# MCASP1_CFG register map
Vendor: Texas Instruments
Peripheral module from a debugger description file (folder TDA2Px).
Registers are 32-bit, read-write, reset values left out (the file's numbers can be read two ways) unless marked. A register's access mark holds for its fields unless they carry their own. Offsets are as the file gives them; lines under a group give offsets from that group; [hi:lo] are bit positions; {n}, {i} and the like mark numbered series; 'fields as' and 'values as' point back to an identical list; <NAME> marks a mode.

## MCASP1_CFG (part 1 of 2)
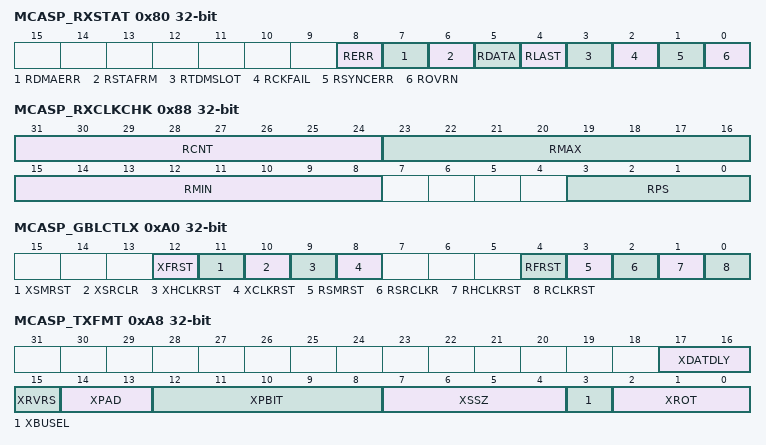
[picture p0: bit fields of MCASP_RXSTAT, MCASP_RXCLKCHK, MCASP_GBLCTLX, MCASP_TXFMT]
0x80 MCASP_RXSTAT — The receiver status register () provides the receiver status and receive TDM time slot number.
  [8] RERR — RERR bit always returns a logic-OR of: ROVRN | RSYNCERR | RCKFAIL | RDMAERR Allows a single bit to be checked to determine if a receiver error has occurred.
    0=NOERROR (No errors have occurred.); 1=ERROR (An error has occurred.)
  [7] RDMAERR — Receive DMA error flag. RDMAERR is set when the CPU or DMA reads more serializers through the DMA port in a given time slot than were programmed as receivers. This bit is cleared by writing a 1 to this bit. Writing a 0 to this bit has no effect.
    0=NOTOCCUR (Receive DMA error did not occur.); 1=OCCUR (Receive DMA error did occur.)
  [6] RSTAFRM — Receive start of frame flag. This bit is cleared by writing a 1 to this bit. Writing a 0 to this bit has no effect.
    0=NOTOCCUR (No new receive frame sync (AFSR) is detected.); 1=OCCUR (A new receive frame sync (AFSR) is detected.)
  [5] RDATA — Receive data ready flag. This bit is cleared by writing a 1 to this bit. Writing a 0 to this bit has no effect.
    0=NOTOCCUR (No new data in RBUF.); 1=OCCUR (Data is transferred from XRSR to RBUF and ready to be serviced by the CPUs or DMA.When RDATA is set, it always causes a DMA event (AREVT).)
  [4] RLAST — Receive last slot flag. RLAST is set along with RDATA, if the current slot is the last slot in a frame. This bit is cleared by writing a 1 to this bit. Writing a 0 to this bit has no effect.
    0=NOTOCCUR (Current slot is not the last slot in a frame.); 1=OCCUR (Current slot is the last slot in a frame. RDATA is also set.)
  [3] RTDMSLOT — Returns the LSB of RSLOT. Allows a single read ofMCASP_RXSTAT to determine whether the current TDM time slot is even or odd.
    0=ODDSLOT (Current TDM time slot is odd.); 1=EVENSLOT (Current TDM time slot is even.)
  [2] RCKFAIL — Receive clock failure flag. RCKFAIL is set when the receive clock failure detection circuit reports an error. This bit is cleared by writing a 1 to this bit. Writing a 0 to this bit has no effect.
    0=NOTOCCUR (Receive clock failure did not occur.); 1=OCCUR (Receive clock failure did occur.)
  [1] RSYNCERR — Unexpected receive frame sync flag. RSYNCERR is set when a new receive frame sync (AFSR) occurs before it is expected. This bit is cleared by writing a 1 to this bit. Writing a 0 to this bit has no effect.
    0=NOTOCCUR (Unexpected receive frame sync did not occur.); 1=OCCUR (Unexpected receive frame sync did occur.)
  [0] ROVRN — Receiver overrun flag. ROVRN is set when the receive serializer is instructed to transfer data from XRSR to RBUF, but the former data in RBUF has not yet been read by the CPU or DMA. This bit is cleared by writing a 1 to this bit. Writing a 0 to this bit has no effect.
    0=NOTOCCUR (Receiver overrun did not occur.); 1=OCCUR (Receiver overrun did occur.)
0x84 MCASP_RXTDMSLOT ro — The current receive TDM time slot register () indicates the current time slot for the receive data frame.
  [8:0] RSLOTCNT — 0x0 - 0x17F: Current receive time slot count. Legal values: 0 to 383 (17Fh). TDM function is not supported for &gt; 32 time slots. However, TDM time slot counter may count to 383 when used to receive a DIR block (transferred over TDM format).
0x88 MCASP_RXCLKCHK access per field — The receive clock check control register (RCLKCHK) configures the receive clock failure detection circuit.
  [31:24] RCNT ro — 0x0 - 0xFF: Receive clock count value (from previous measurement). The clock circuit continually counts the number of interface clocks for every 32 receive high-frequency master clock (AHCLKR) signals, and stores the count in RCNT until the next measurement is taken.
  [23:16] RMAX rw — 0x00-0xFF: Receive clock maximum boundary. This 8-bit unsigned value sets the maximum allowed boundary for the clock check counter after 32 receive high-frequency master clock (AHCLKR) signals have been received. If the current counter value is greater than RMAX after counting 32 AHCLKR signals, RCKFAIL inMCASP_RXSTAT is set. The comparison is performed using unsigned arithmetic.
  [15:8] RMIN rw — 0x00 - 0xFF: Receive clock minimum boundary. This 8-bit unsigned value sets the minimum allowed boundary for the clock check counter after 32 receive high-frequency master clock (AHCLKR) signals have been received. If RCNT is less than RMIN after counting 32 AHCLKR signals, RCKFAIL in RSTAT is set. The comparison is performed using unsigned arithmetic.
  [3:0] RPS rw — Receive clock check prescaler value.0x9 - 0xF: Reserved enum=DIVBY8 .
    0=DIVBY64 (MCASP interface clock divided by 1); 1=DIVBY2 (MCASP interface clock divided by 2); 2=DIVBY128 (MCASP interface clock divided by 4); 3=DIVBY1 (MCASP interface clock divided by 8); 4=DIVBY4 (MCASP interface clock divided by 16); 5=DIVBY256 (MCASP interface clock divided by 32); 6=DIVBY16 (MCASP interface clock divided by 64); 7=DIVBY32 (MCASP interface clock divided by 128); 8=DIVBY8 (MCASP interface clock divided by 256)
0x8C MCASP_REVTCTL — Receiver DMA event control register
  [0] RDATDMA — Receive data DMA request enable bit.
    0=DMA_0 (The receive data DMA request is enabled.); 1=DMA_1 (The receive data DMA request is disabled.)
0xA0 MCASP_GBLCTLX access per field — Alias of GBLCTL. When writing to this register, only the TRANSMIT bits of GBLCTL are affected (This means GBLCTL bits 8,9,10,11,12.). Reads return GBLCTL.
  [12] XFRST rw — Frame sync generator reset
    0=RESET; 1=ACTIVE
  [11] XSMRST rw — XMT state machine reset
    0=RESET; 1=ACTIVE
  [10] XSRCLR rw — XMT serializer clear
    0=CLEAR; 1=ACTIVE
  [9] XHCLKRST rw — XMT High Freq. clk Divider
    0=RESET; 1=ACTIVE
  [8] XCLKRST rw — XMT clock divder reset
    0=RESET; 1=ACTIVE
  [4] RFRST ro — Frame sync generator reset
    0=RESET; 1=ACTIVE
  [3] RSMRST ro — RCV state machine reset
    0=RESET; 1=ACTIVE
  [2] RSRCLKR ro — RCV serializer clear
    0=CLEAR; 1=ACTIVE
  [1] RHCLKRST ro — RCV High Freq. clk Divider
    0=RESET; 1=ACTIVE
  [0] RCLKRST ro — RCV clock divder reset
    0=RESET; 1=ACTIVE
0xA4 MCASP_TXMASK — Transmit format unit bit mask register - Determines which bits of the transmitted data are masked off before being shifted out the MCASP
  [31:0] XMASK_31_0 — Transmit data mask enable bit
    0=MCASP_0 (The corresponding bit of transmit data is masked out and then transmitted out the MCASP in place of the original bit.); 1=MCASP._1 (The corresponding bit of transmit data is transmitted out the MCASP.)
0xA8 MCASP_TXFMT — Transmit bitstream format register - configures the transmit data format
  [17:16] XDATDLY — Transmit sync bit delay
    0=0BIT (0 bit delay - The first transmit data bit, on the AXR[n], occurs in the same mcaspi_aclkx cycle as the transmit frame sync (mcaspi_fsx).); 1=1BIT (1-bit delay. The first transmit data bit, AXR[n], occurs one ACLKX cycle after the transmit frame sync (AFSX).); 2=2BIT (2-bit delay. The first transmit data bit, AXR[n], occurs two ACLKX cycles after the transmit frame sync (AFSX).); 3=2BIT (Reserved)
  [15] XRVRS — Transmit serial bitstream order
    0=LSB_0 (Bitstream is LSB first. No bit reversal is performed in transmit format unit.); 1=MSB_1 (Bitstream is MSB first. Bit reversal is performed in transmit format bit reverse unit.)
  [14:13] XPAD — Pad value for extra bits in slot not belonging to word defined by XMASK. This field only applies to bits when XMASK[n] = 0.
    0=Pad_extra_bits_with_0; 1=Pad_extra_bits_with_1; 2=XPBIT_2 (Pad extra bits with one of the bits from the word as specified by XPBIT bits.)
  [12:8] XPBIT — XPBIT value determines which bit (as written by the CPU or DMA to XBUF[n]) is used to pad the extra bits before shifting. This field only applies when XPAD = 0x2.
  [7:4] XSSZ — Transmit slot size0x0 - 0x2 : Reserved enum=RSV8 .
    3=RSV8 (Slot size is 8 bits); 4=RSV8 (Reserved); 5=RSV8 (Slot size is 12 bits); 6=RSV8 (Reserved); 7=RSV8 (Slot size is 16 bits); 8=RSV8 (Reserved); 9=RSV8 (Slot size is 20 bits); 10=RSV8 (Reserved); 11=RSV8 (Slot size is 24 bits); 12=RSV8 (Reserved); 13=RSV8 (Slot size is 28 bits); 14=RSV8 (Reserved); 15=Slot_size_is_32_bits
  [3] XBUSEL — Selects whether writes to the serializer buffer XBUF[n] originate from the peripheral configuration CFG port or the DATA port.
    0=VBUSP (Writes to XBUF[n] originate from the DATA port. Writes to XBUF[n] from the peripheral configuration port are ignored with no effect on the MCASP.); 1=VBUS (Writes to XBUF[n] originate from the peripheral configuration port - CFG port. Writes to XBUF[n] from the DATA port are ignored with no effect on the MCASP.)
  [2:0] XROT — Right-rotation value for transmit rotate right format unit
    0=12BITS (Rotate right by 0 (no rotation).); 1=Rotate_right_by_4_bit_positions; 2=Rotate_right_by_8_bit_positions; 3=Rotate_right_by_12_bit_positions; 4=Rotate_right_by_16_bit_positions; 5=Rotate_right_by_20_bit_positions; 6=Rotate_right_by_24_bit_positions; 7=Rotate_right_by_28_bit_positions
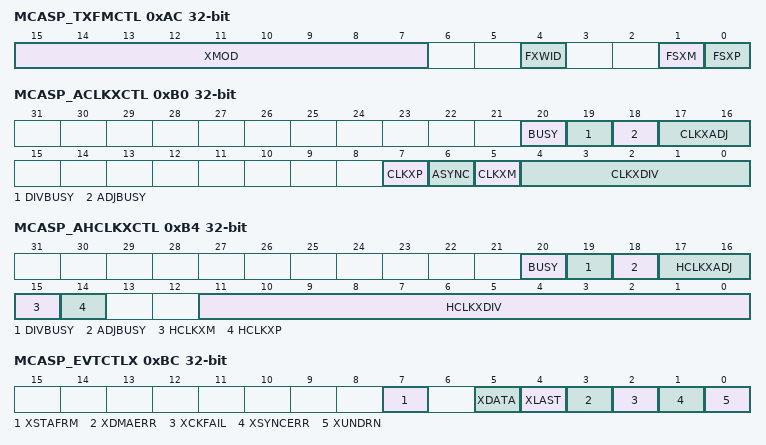
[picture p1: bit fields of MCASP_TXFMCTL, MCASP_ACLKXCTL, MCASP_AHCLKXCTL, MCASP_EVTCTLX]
0xAC MCASP_TXFMCTL — Transmit frame-sync control register - configures the transmit frame sync (mcaspi_fsx).
  [15:7] XMOD — Transmit frame-sync mode select bits 0x0: Burst mode 0x1: Reserved 0x2: 2-slot TDM mode (I2S transmit mode) 0x3 - 0x20: 3-slot TDM to 32-slot TDM mode 0x21 - 0x17F: Reserved 0x180: 384-slot DIT mode All other: Reserved
  [4] FXWID — The transmit frame-sync width select bit indicates the width of the transmit frame sync (mcaspi_fsx) during its active period.
    0=WORD (Single bit); 1=XMOD_1 (Single word. Single word is not supported if XMOD is set to burst mode.)
  [1] FSXM — Transmit frame-sync generation select bit
    0=INTERNAL (Externally-generated transmit frame); 1=Internally-generated transmit frame sync
  [0] FSXP — Transmit frame-sync polarity select bit
    0=FALLINGEDGE (Rising Edge - A rising edge on transmit frame sync (mcaspi_fsx) indicates the beginning of a frame.); 1=A_1 (Falling Edge - A falling edge on transmit frame sync (mcaspi_fsx) indicates the beginning of a frame.)
0xB0 MCASP_ACLKXCTL access per field — Transmit clock control register - Configures the transmit bit clock (mcaspi_aclkx) and the transmit clock generator.
  [20] BUSY rw — Status: logical OR of DIVBUSY, ADJBUSY. Not supported.
    0=NOTBUSY; 1=BUSY
  [19] DIVBUSY rw — Status: divide ratio change in progress? Not supported.
    0=NOTBUSY; 1=BUSY
  [18] ADJBUSY rw — Status: one-shot adjustment in progress? Not supported.
    0=NOTBUSY; 1=BUSY
  [17:16] CLKXADJ wo — CLKXDIV one-shot adjustment. Not supported. Bit field must always be written as 0x0. If CLKXDIV is set such that there are “m” input clocks per one output clock, then for one output cycle:00 = (m+0) input clocks per output clock, i.e. no adjustment . 01 = (m-1) input clocks per output clock . 10 = (m+1) input clocks per output clock . 11 = (m+0) input clocks per output clock, i.e. no adjustment . NOTE: writes to these bits are ineffective if CLKADJEN:ENABLE bit is set to 0b. These bits are ALWAYS read back as zero. .
  [7] CLKXP rw — Transmit bitstream clock polarity select bit.
    0=Rising edge. External receiver samples data on the falling edge of the serial clock, so the transmitter must shift data out on the rising edge of the serial clock.; 1=Falling edge. External receiver samples data on the rising edge of the serial clock, so the transmitter must shift data out on the falling edge of the serial clock.
  [6] ASYNC rw — Transmit operation asynchronous enable bit
    0=ASYNC (Synchronous. Transmit clock and frame sync provides the source for both the transmit and receive sections. Note that in this mode, the receive bit clock is an inverted version of the transmit bit clock.); 1=Asynchronous. Separate clock and frame sync used by transmit and receive sections.
  [5] CLKXM rw — Transmit bit clock source bit
    0=INTERNAL (External transmit clock source from ACLKX pin.); 1=Internal_(output_of_divider)
  [4:0] CLKXDIV rw — Transmit bit clock divide ratio bits, determine the divide-down ratio from AHCLKX to ACLKX. 0x0: Divide-by-1 0x1: Divide-by-2 0x2 to 0x1F: Divide-by-3 to divide-by-32
0xB4 MCASP_AHCLKXCTL access per field — High-frequency transmit clock control register - Configures the transmit high-frequency master clock (mcaspi_ahclkx) and the transmit clock generator.
  [20] BUSY rw — Status: logical OR of DIVBUSY, ADJBUSY. Not supported.
    0=NOTBUSY; 1=BUSY
  [19] DIVBUSY rw — Status: divide ratio change in progress? Not supported.
    0=NOTBUSY; 1=BUSY
  [18] ADJBUSY rw — Status: one-shot adjustment in progress? Not supported.
    0=NOTBUSY; 1=BUSY
  [17:16] HCLKXADJ wo — HCLKXDIV one-shot adjustment. Not supported. Bit field must always be written as 0x0. If HCLKXDIV is set such that there are “m” input clocks per one output clock, then for one output cycle:00 = (m+0) input clocks per output clock, i.e. no adjustment . 01 = (m-1) input clocks per output clock . 10 = (m+1) input clocks per output clock . 11 = (m+0) input clocks per output clock, i.e. no adjustment . NOTE: writes to these bits are ineffective if CLKADJEN:ENABLE bit is set to 0b. These bits are ALWAYS read back as zero. .
  [15] HCLKXM rw — Transmit high-frequency clock source bit
    0=INTERNAL (External transmit high-frequency clock source from AHCLKX pin.); 1=Internal transmit high-frequency clock source from output of programmable high clock divider
  [14] HCLKXP rw — Transmit bitstream high-frequency clock polarity select bit.
    0=AHCLKX_0 (Not inverted. AHCLKX is not inverted before programmable bit clock divider.); 1=AHCLKX_1 (Inverted. AHCLKX is inverted before programmable bit clock divider.)
  [11:0] HCLKXDIV rw — Transmit high-frequency clock divide ratio bits determine the divide-down ratio from AUXCLK to mcaspi_ahclkx. 0x0: Divide-by-1 0x1: Divide-by-2 0x2 to 0xFFF: Divide-by-3 to divide-by-4096
0xB8 MCASP_TXTDM — Transmit TDM slot 0-31 register - TDM time slot counter range is to 384 slots (to support SPDIF blocks of 384 subframes).
  [31:0] XTDMS_31_0 — Transmitter mode during TDM time slot n (n = 0..31)
    0=TDM_0 (Transmit TDM time slot n is inactive. The transmit serializer does not shift out data during this slot.); 1=TDM_1 (The transmit TDM time slot n is active. The transmit serializer shifts out data during this slot according to the serializer control registers -.)
0xBC MCASP_EVTCTLX — Transmitter Interrupt control register - controls generation of the MCASP transmit interrupt (XINT). When the register bit(s) is set to 1, the occurrence of the enabled MCASP condition(s) generates XINT.
  [7] XSTAFRM — Transmit start of frame interrupt enable bit
    0=ENABLE (Interrupt is disabled. A transmit-start-of-frame interrupt does not generate a MCASP transmit interrupt (XINT).); 1=A_MCASP_(XINT)._1 (Interrupt is enabled. A transmit-start-of-frame interrupt generates a MCASP transmit interrupt (XINT).)
  [5] XDATA — Transmit data-ready interrupt enable bit
    0=ENABLE (Interrupt is disabled. A transmit data-ready interrupt does not generate a MCASP transmit interrupt (XINT).); 1=A_MCASP_(XINT)._1 (Interrupt is enabled. A transmit data-ready interrupt generates a MCASP transmit interrupt (XINT).)
  [4] XLAST — Transmit last slot interrupt enable bit
    0=ENABLE (Interrupt is disabled. A transmit-last-slot interrupt does not generate a MCASP transmit interrupt (XINT).); 1=A_MCASP_(XINT)._1 (Interrupt is enabled. A transmit-last-slot interrupt generates a MCASP transmit interrupt (XINT).)
  [3] XDMAERR — Transmit DMA error interrupt enable bit
    0=ENABLE (Interrupt is disabled. A transmit DMA error interrupt does not generate a MCASP transmit interrupt (XINT).); 1=A_DMA_MCASP_(XINT)._1 (Interrupt is enabled. A transmit DMA error interrupt generates a MCASP transmit interrupt (XINT).)
  [2] XCKFAIL — Transmit clock failure interrupt enable bit
    0=ENABLE (Interrupt is disabled. A transmit clock failure interrupt does not generate a MCASP transmit interrupt (XINT).); 1=A_MCASP_(XINT)._1 (Interrupt is enabled. A transmit clock failure interrupt generates a MCASP transmit interrupt (XINT).)
  [1] XSYNCERR — Unexpected transmit frame-sync interrupt enable bit
    0=ENABLE (Interrupt is disabled. An unexpected transmit frame-sync interrupt does not generate a MCASP transmit interrupt (XINT).); 1=MCASP_(XINT)._1 (Interrupt is enabled. An unexpected transmit frame-sync interrupt generates a MCASP transmit interrupt (XINT).)
  [0] XUNDRN — Transmitter underrun interrupt enable bit
    0=ENABLE (Interrupt is disabled. A transmitter underrun interrupt does not generate a MCASP transmit interrupt (XINT).); 1=A_MCASP_(XINT)._1 (Interrupt is enabled. A transmitter underrun interrupt generates a MCASP transmit interrupt (XINT).)
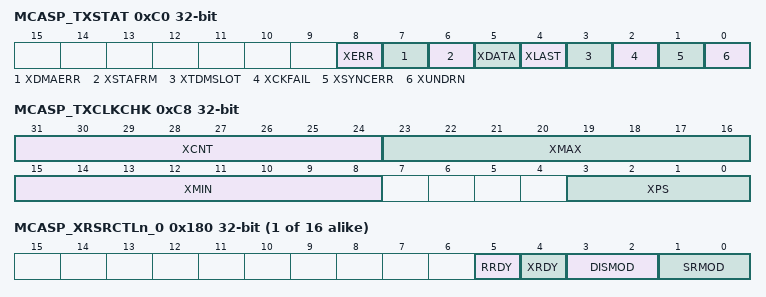
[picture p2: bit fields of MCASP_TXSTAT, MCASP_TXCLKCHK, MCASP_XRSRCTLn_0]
0xC0 MCASP_TXSTAT access per field — Transmitter status register - If the MCASP logic attempts to set an interrupt flag in the same cycle that the CPU writes to the flag to clear it, the MCASP logic has priority and the flag remains set. This also causes the generation of a new interrupt request.
  [8] XERR rw — XERR bit always returns a logic-OR of: XUNDRN | XSYNCERR | XCKFAIL | XDMAERR. Allows a single bit to be checked to determine if a transmitter error interrupt has occurred.
    0=ERROR (No errors have occurred.); 1=An_error_has_occurred
  [7] XDMAERR rw — Transmit DMA error flag. XDMAERR is set when the CPU or DMA writes more words to the DATA port of the MCASP in a given time slot than it should. Causes a transmit interrupt (XINT) if this bit and XDMAERR inMCASP_EVTCTLX are set. This bit is cleared by writing a 1 to it. Writing a 0 has no effect.
    0=OCCUR (Transmit DMA error did not occur.); 1=Transmit_DMA_error_occurred
  [6] XSTAFRM rw — Transmit start of frame flag. Causes a transmit interrupt (XINT) if this bit and XSTAFRM inMCASP_EVTCTLX are set. This bit is cleared by writing a 1 to it. Writing a 0 has no effect.
    0=OCCUR (No new transmit frame sync (AFSX) is detected.); 1=A_(AFSX)_1 (A new transmit frame sync (AFSX) is detected.)
  [5] XDATA rw — Transmit data ready flag. Causes a transmit interrupt (XINT) if this bit and XDATA inMCASP_EVTCTLX are set. This bit is cleared by writing a 1 to iit. Writing a 0 has no effect
    0=OCCUR (XBUF[n] is written and is full); 1=XDATA_XDATA_DMA_(AXEVT)._1 (Data is copied from XBUF[n] to XRSR[n]. XBUF[n] is empty and ready to be written. XDATA is also set when the transmit serializers are taken out of reset. When XDATA is set, it always causes a DMA event (AXEVT).)
  [4] XLAST rw — Transmit last slot flag. XLAST, along with XDATA, are set if the current slot is the last slot in a frame. Causes a transmit interrupt (XINT) if this bit and XLAST inMCASP_EVTCTLX are set. This bit is cleared by writing a 1 to iit. Writing a 0 has no effect.
    0=OCCUR (Current slot is not the last slot in a frame.); 1=XDATA_1 (Current slot is the last slot in a frame. XDATA is also set.)
  [3] XTDMSLOT ro — Returns the LSB of XSLOT. Allows a single read of XSTAT to determine whether the current TDM time slot is even or odd.
    0=EVENSLOT (Current TDM time slot is odd.); 1=Current_TDM_time_slot_is_even
  [2] XCKFAIL rw — Transmit clock failure flag. XCKFAIL is set when the transmit clock failure detection circuit reports an error. Causes a transmit interrupt (XINT) if this bit and XCKFAIL inMCASP_EVTCTLX are set. This bit is cleared by writing a 1 to iit. Writing a 0 has no effect.
    0=OCCUR (Transmit clock failure did not occur.); 1=Transmit_clock_failure_occurred
  [1] XSYNCERR rw — Unexpected transmit frame-sync flag. XSYNCERR is set when a new transmit frame sync (AFSX) occurs before it is expected. Causes a transmit interrupt (XINT) if this bit and XSYNCERR inMCASP_EVTCTLX are set. This bit is cleared by writing a 1 to iit. Writing a 0 has no effect.
    0=OCCUR (Unexpected transmit frame sync did not occur); 1=Unexpected transmit frame sync occurred
  [0] XUNDRN rw — Transmitter underrun flag. XUNDRN is set when the transmit serializer is instructed to transfer data from XBUF[n] to XRSR[n], but XBUF[n] has not yet been serviced with new data since the last transfer. Causes a transmit interrupt (XINT) if this bit and XUNDRN inMCASP_EVTCTLX are set. This bit is cleared by writing a 1 to iit. Writing a 0 has no effect.
    0=OCCUR (Transmitter underrun did not occur); 1=Transmitter_underrun_occurred
0xC4 MCASP_TXTDMSLOT ro — Current transmit TDM time slot register
  [8:0] XSLOTCNT — Current transmit time slot count. the value of this register is 0b0101111111 (0x17f) during reset and 0 after reset.
0xC8 MCASP_TXCLKCHK access per field — Transmit clock check control register - configures the transmit clock failure detection circuit.
  [31:24] XCNT ro — Transmit clock count value (from previous measurement). The clock circuit continually counts the number of interface clocks for every 32 transmit high-frequency master clock (mcaspi_ahclkx) signals, and stores the count in XCNT until the next measurement is taken
  [23:16] XMAX rw — 0x0 to 0xFF: Transmit clock maximum boundary. This 8-bit unsigned value sets the maximum allowed boundary for the clock check counter after 32 transmit high-frequency master clock (mcaspi_ahclkx) signals have been received. If the current counter value is greater than XMAX after counting 32 AHCLKX signals, XCKFAIL in XSTAT is set. The comparison is performed using unsigned arithmetic.
  [15:8] XMIN rw — 0x0 to 0xFF: Transmit clock minimum boundary. This 8-bit unsigned value sets the minimum allowed boundary for the clock check counter after 32 transmit high-frequency master clock (mcaspi_ahclkx) signals have been received. If XCNT is less than XMIN after counting 32 AHCLKX signals, XCKFAIL in XSTAT is set. The comparison is performed using unsigned arithmetic.
  [3:0] XPS rw — Transmit clock check prescaler value 0x0: MCASP interface clock divided by 1 0x1: MCASP interface clock divided by 2 0x2: MCASP interface clock divided by 4 0x3: MCASP interface clock divided by 8 0x4: MCASP interface clock divided by 16 0x5: MCASP interface clock divided by 32 0x6: MCASP interface clock divided by 64 0x7: MCASP interface clock divided by 128 0x8: MCASP interface clock divided by 256 0x9 to 0xF: Reserved
0xCC MCASP_XEVTCTL — Transmitter DMA event control register
  [0] XDATDMA — Transmit data DMA request enable bit.
    0=DMA_0 (The transmit data DMA request is enabled.); 1=DMA_1 (The transmit data DMA request is disabled.)
0xD0 MCASP_CLKADJEN — One-Shot Clock Adjustment Enable
  [0] ENABLE — One-shot clock adjust enable. Not supported. Bit field must always be written as 0x0.
    0=DISABLE; 1=ENABLE
{0x100+4i} MCASP_DITCSRAi_{i} (i=0..5) — DIT left channel status register - All six 32-bit registers (i = 0 to 5) can store 192 bits of channel status data for a complete block of transmission. The DIT reuses the same data for the next block. Make sure to update the register file before a different set of data needs to be sent.
  [31:0] DITCSRAi — Left (even TDM slot ) channel status
{0x118+4i} MCASP_DITCSRBi_{i} (i=0..5) — DIT right channel status register - All six 32-bit registers (i = 0 to 5) can store 192 bits of channel status data for a complete block of transmission. The DIT reuses the same data for the next block. Make sure to update the register file before a different set of data needs to be sent.
  [31:0] DITCSRBi — Right (odd TDM slot ) channel status
{0x130+4i} MCASP_DITUDRAi_{i} (i=0..5) — DIT left channel user data register - provides the user data of each left channel (even TDM time slot). All six 32-bit registers (i = 0 to 5) can store 192 bits of user data for a complete block of transmission. The DIT reuses the same data for the next block. Make sure to update the register before a different set of data needs to be sent.
  [31:0] DITUDRAi — Left (even TDM slot ) user data
{0x148+4i} MCASP_DITUDRBi_{i} (i=0..5) — DIT right user data register - provides the user data of each right channel (odd TDM time slot). All six 32-bit registers (i = 0 to 5) can store 192 bits of user data for a complete block of transmission. The DIT reuses the same data for the next block. Make sure to update the register before a different set of data needs to be sent.
  [31:0] DITUDRBi — Right (odd TDM slot ) user data
{0x180+4i} MCASP_XRSRCTLn_{i} access per field (i=0..15) — Serializer n control register.
  [5] RRDY ro — Receive buffer ready bit. RRDY indicates the current receive buffer state. Always reads 0 when programmed as a transmitter or as inactive. If SRMOD bit is set to receive (2h), RRDY switches from 0 to 1 whenever data is transferred from XRSRn to RBUFn.
    0=Receive_buffer_()_is_empty; 1=RRDY_1_r (Receive buffer () contains data and needs to be read before the start of the next time slot or a receiver overrun occurs.)
  [4] XRDY ro — Transmit buffer ready bit. XRDY indicates the current transmit buffer state. Always reads 0 when programmed as a receiver or as inactive. If SRMOD bit is set to transmit (1h), XRDY switches from 0 to 1 when XSRCLR in GBLCTL is switched from 0 to 1 to indicate an empty transmitter. XRDY remains set until XSRCLR is forced to 0, data is written to the corresponding transmit buffer, or SRMOD bit is changed to receive (2h) or inactive (0).
    0=DATA (The transmit buffer () contains data.); 1=XRDY_1_r (The transmit buffer () is empty and needs to be written before the start of the next time slot or a transmit underrun occurs.)
  [3:2] DISMOD rw — Serializer pin drive mode bit. Drive on pin when in inactive TDM slot of transmit mode or when serializer is inactive. This field only applies if the pin is configured as a MCASP pin (PFUNC = 0).
    0=Drive_on_pin_is_3-state; 2=Drive_on_pin_is_logic_low; 3=Drive_on_pin_is_logic_high
  [1:0] SRMOD rw — Serializer mode bit
    0=INACTIVE (The serializer is inactive); 1=RCV (The serializer is operating in transmit mode.); 2=RCV (The serializer is operating in receive mode.); 3=RCV (Reserved)
{0x200+4i} MCASP_TXBUFn_{i} (i=0..15) — Transmit buffer n - The transmit buffer for the serializer n holds data from the transmit format unit.
  [31:0] XBUFn — Transmit buffer n
{0x280+4i} MCASP_RXBUFn_{i} (i=0..15) — Receive buffer n - The receive buffer for the serializer n holds data before the data goes to the receive format unit.
  [31:0] RBUFn — Receive Buffer n
